# MCXN947_cm33_core0 register map
Vendor: nxp.com; File version: 1.0
CPU: CM33 r2p0, little endian, MPU, FPU, VTOR, 3 interrupt priority bits
Registers are 32-bit, read-write, reset 0x0 unless marked. A register's access mark holds for its fields unless they carry their own. Offsets are from the block's base; [hi:lo] are bit positions; {n}, {i} and the like mark numbered series; 'fields as' and 'values as' point back to an identical list.

## SYSCON0 (part 2 of 2) — SYSCON
Base 0x40000000
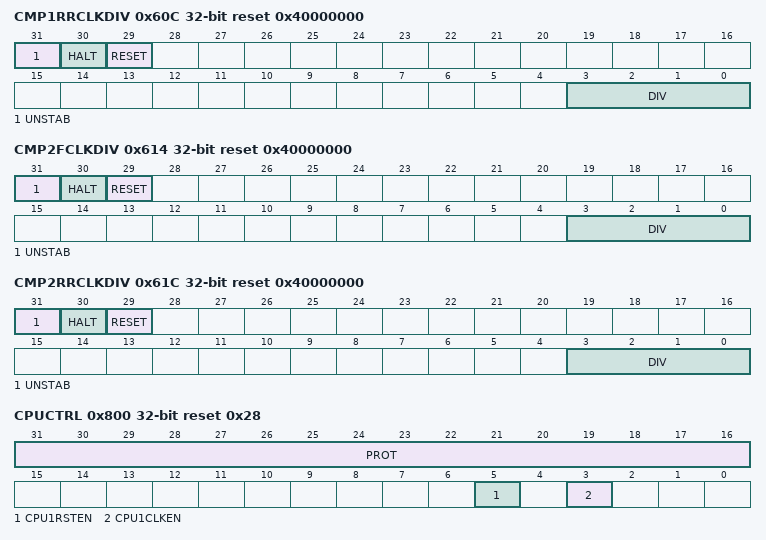
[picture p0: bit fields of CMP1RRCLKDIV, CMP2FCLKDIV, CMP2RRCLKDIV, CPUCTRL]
0x60C CMP1RRCLKDIV reset 0x40000000 — CMP1 Round Robin Clock Division
  [31] UNSTAB ro — Divider status flag
    0=STABLE (Divider clock is stable); 1=ONGOING (Clock frequency is not stable)
  [30] HALT — Halts the divider counter
    0=RUN (Divider clock is running); 1=HALT (Divider clock is stopped)
  [29] RESET — Resets the divider counter
    0=RELEASED (Divider is not reset); 1=ASSERTED (Divider is reset)
  [3:0] DIV — Clock divider value
0x610 CMP2FCLKSEL reset 0x7 — CMP2 Function Clock Source Select
  [2:0] SEL — Selects the CMP2 function clock
    0=No clock; 1=PLL0 clock; 2=FRO_HF clock; 3=FRO_12M clock; 4=CLKIN clock; 5=PLL1_clk0 clock; 6=USB PLL clock; 7=No clock
0x614 CMP2FCLKDIV reset 0x40000000 — CMP2 Function Clock Division
  fields as CMP1RRCLKDIV
0x618 CMP2RRCLKSEL reset 0x7 — CMP2 Round Robin Clock Source Select
  [2:0] SEL — Selects the CMP2 round robin clock
    0=No clock; 1=PLL0 clock; 2=FRO_HF clock; 3=FRO_12M clock; 4=CLKIN clock; 5=PLL1_clk0 clock0; 6=USB PLL clock; 7=No clock
0x61C CMP2RRCLKDIV reset 0x40000000 — CMP2 Round Robin Clock Division
  fields as CMP1RRCLKDIV
0x800 CPUCTRL reset 0x28 — CPU Control for Multiple Processors
  [31:16] PROT wo — Write Protect
    0xC0C4=PROT (For write operation to have an effect.)
  [5] CPU1RSTEN — CPU1 reset
    0=RELEASED (The CPU1 is not reset.); 1=ASSERTED (The CPU1 is reset.)
  [3] CPU1CLKEN — Enables the CPU1 clock
    0=DISABLE (The CPU1 clock is not enabled); 1=ENABLE (The CPU1 clock is enabled)
0x804 CPBOOT — Coprocessor Boot Address
  [31:7] CPBOOT — Coprocessor Boot VTOR Address [31:7] for CPU1
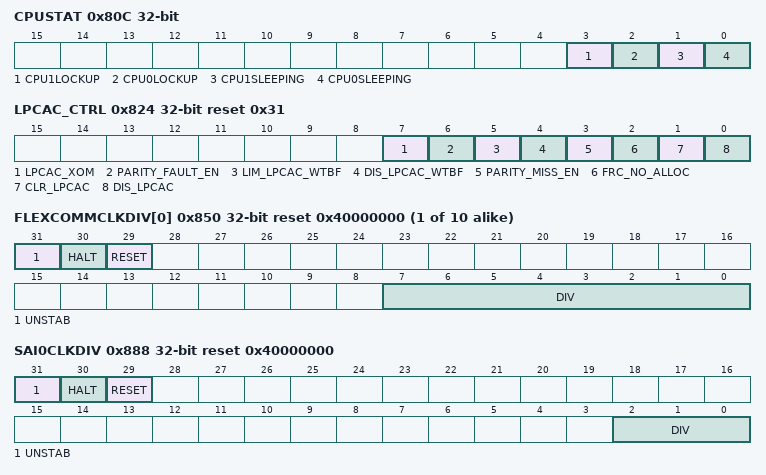
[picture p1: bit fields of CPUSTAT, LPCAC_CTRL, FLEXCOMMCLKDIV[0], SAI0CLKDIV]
0x80C CPUSTAT ro — CPU Status
  [3] CPU1LOCKUP — CPU1 lockup state
    0=AWAKE (CPU is not in lockup); 1=SLEEPING (CPU is in lockup)
  [2] CPU0LOCKUP — CPU0 lockup state
    values as CPU1LOCKUP
  [1] CPU1SLEEPING — CPU1 sleeping state
    0=AWAKE (CPU is not sleeping); 1=SLEEPING (CPU is sleeping)
  [0] CPU0SLEEPING — CPU0 sleeping state
    0=AWAKE (CPU is not sleeping); 1=SLEEPING (CPU is sleeping)
0x824 LPCAC_CTRL reset 0x31 — LPCAC Control
  [7] LPCAC_XOM — LPCAC XOM(eXecute-Only-Memory) attribute control
    0=DISABLE (Disabled.); 1=ENABLE (Enabled.)
  [6] PARITY_FAULT_EN — Enable parity error report.
    0=DISABLE (Disables parity error report); 1=ENABLE (Enables parity error report)
  [5] LIM_LPCAC_WTBF — Limit LPCAC Write Through Buffer.
    0=DISABLE (Write buffer enabled when transaction is bufferable.); 1=ENABLE (Write buffer enabled when transaction is cacheable and bufferable)
  [4] DIS_LPCAC_WTBF — Disable LPCAC Write Through Buffer.
    0=DISABLE (Enables write through buffer); 1=ENABLE (Disables write through buffer)
  [3] PARITY_MISS_EN — Enables parity miss.
    0=DISABLE (Disabled); 1=ENABLE (Enables parity, miss on parity error)
  [2] FRC_NO_ALLOC — Forces no allocation.
    0=ENABLE (Forces allocation); 1=DISABLE (Forces no allocation)
  [1] CLR_LPCAC — Clears the cache function.
    0=ENABLE (Unclears the cache); 1=DISABLE (Clears the cache)
  [0] DIS_LPCAC — Disables/enables the cache function.
    0=ENABLE (Enabled); 1=DISABLE (Disabled)
{0x850+4i} FLEXCOMMCLKDIV[{i}] (i=0..9) reset 0x40000000 — LP_FLEXCOMM Clock Divider
  [31] UNSTAB ro — Divider status flag
    values as CMP1RRCLKDIV.UNSTAB
  [30] HALT — Halts the divider counter
    values as CMP1RRCLKDIV.HALT
  [29] RESET — Resets the divider counter
    values as CMP1RRCLKDIV.RESET
  [7:0] DIV — Clock divider value
0x878 UTICKCLKSEL reset 0x2 — UTICK Function Clock Source Select
  [1:0] SEL — Selects the clock source
    0=clk_in; 1=xtal32k[2]; 2=clk_1m clock; 3=No clock
0x880 SAI0CLKSEL reset 0x7 — SAI0 Function Clock Source Select
  [2:0] SEL — Selects the clock source
    0=No clock; 1=PLL0 clock; 2=CLKIN clock; 3=FRO_HF clock; 4=PLL1_CLK0 clock; 5=No clock; 6=USB PLL clock; 7=No clock
0x884 SAI1CLKSEL reset 0x7 — SAI1 Function Clock Source Select
  fields as SAI0CLKSEL
0x888 SAI0CLKDIV reset 0x40000000 — SAI0 Function Clock Division
  [31] UNSTAB ro — Divider status flag
    values as CMP1RRCLKDIV.UNSTAB
  [30] HALT — Halts the divider counter
    values as CMP1RRCLKDIV.HALT
  [29] RESET — Resets the divider counter
    values as CMP1RRCLKDIV.RESET
  [2:0] DIV — Clock divider value
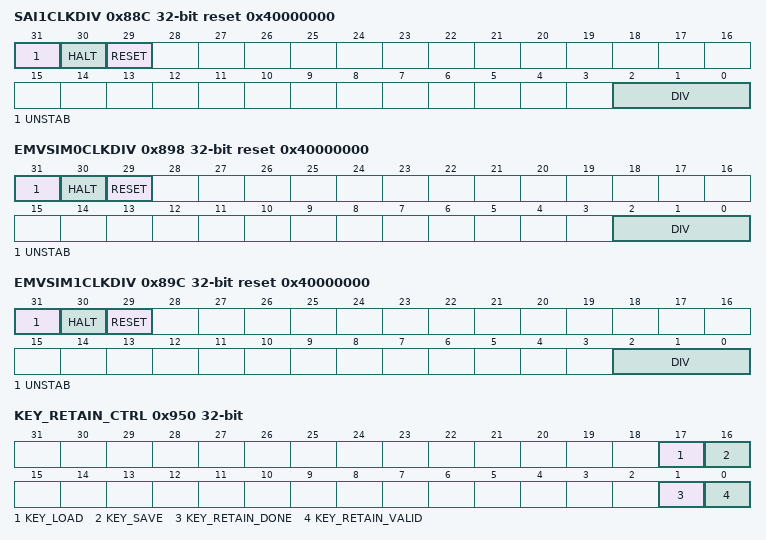
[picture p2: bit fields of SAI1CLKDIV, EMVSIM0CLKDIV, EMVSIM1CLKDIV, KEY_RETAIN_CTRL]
0x88C SAI1CLKDIV reset 0x40000000 — SAI1 Function Clock Division
  fields as SAI0CLKDIV
0x890 EMVSIM0CLKSEL reset 0x7 — EMVSIM0 Clock Source Select
  [2:0] SEL — Selects the EMVSIM0 function clock source
    0=No clock; 1=PLL0 clock; 2=CLKIN clock; 3=FRO_HF clock; 4=FRO_12M clock; 5=PLL1_clk0 clock0; 6=No clock; 7=No clock
0x894 EMVSIM1CLKSEL reset 0x7 — EMVSIM1 Clock Source Select
  [2:0] SEL — Selects the EMVSIM1 function clock source
    values as EMVSIM0CLKSEL.SEL
0x898 EMVSIM0CLKDIV reset 0x40000000 — EMVSIM0 Function Clock Division
  fields as SAI0CLKDIV
0x89C EMVSIM1CLKDIV reset 0x40000000 — EMVSIM1 Function Clock Division
  fields as SAI0CLKDIV
0x950 KEY_RETAIN_CTRL — Key Retain Control
  [17] KEY_LOAD — Do not set both KEY_SAVE and KEY_LOAD at the same time
    0=DISABLE (Key load sequence is disabled.); 1=ENABLE (Key load sequence is enabled.)
  [16] KEY_SAVE — Do not set both KEY_SAVE and KEY_LOAD at the same time
    0=DISABLE (Key save sequence is disabled.); 1=ENABLE (Key save sequence is enabled.)
  [1] KEY_RETAIN_DONE ro — Indicates the successful completion of the key_save or key_load routine. Once set, to clear the key_retain_done flag, both key_save and key_load should be cleared by software.
    0=NOT_DONE (Key save / load sequence has not completed.); 1=DONE (Key save / load sequence has completed.)
  [0] KEY_RETAIN_VALID ro — Indicates if the PUF key has been retained in the VBAT domain and has not been reset or otherwise invalidated by software.
    0=NOT_VALID (PUF key is not retained in VBAT domain.); 1=VALID (PUF key is retained in VBAT domain.)
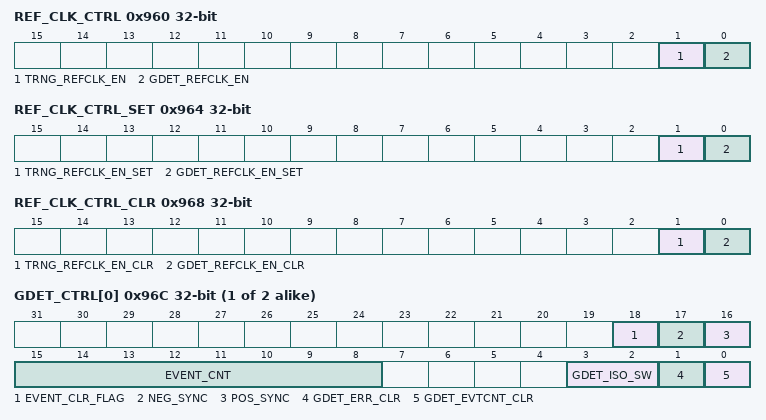
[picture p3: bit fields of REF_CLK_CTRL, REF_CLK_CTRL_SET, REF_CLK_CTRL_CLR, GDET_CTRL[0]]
0x960 REF_CLK_CTRL — FRO 48MHz Reference Clock Control
  [1] TRNG_REFCLK_EN — ELS TRNG reference clock enable bit
    0=DISABLE (Disabled.); 1=ENABLE (Enabled)
  [0] GDET_REFCLK_EN — GDET reference clock enable bit
    0=DISABLE (Disabled.); 1=ENABLE (Enabled)
0x964 REF_CLK_CTRL_SET wo — FRO 48MHz Reference Clock Control Set
  [1] TRNG_REFCLK_EN_SET — ELS TRNG reference clock enable set bit
    0=DISABLE (No effect.); 1=ENABLE (Set to 1)
  [0] GDET_REFCLK_EN_SET — GDET reference clock enable set bit
    0=DISABLE (No effect.); 1=ENABLE (Set to 1)
0x968 REF_CLK_CTRL_CLR wo — FRO 48MHz Reference Clock Control Clear
  [1] TRNG_REFCLK_EN_CLR — ELS TRNG reference clock enable clear bit
    0=DISABLE (No effect.); 1=ENABLE (Set to 0)
  [0] GDET_REFCLK_EN_CLR — GDET reference clock enable clear bit
    0=DISABLE (No effect.); 1=ENABLE (Set to 0)
{0x96C+4i} GDET_CTRL[{i}] (i=0..1) — GDET Control Register
  [18] EVENT_CLR_FLAG ro — Event counter cleared
    0=DISABLE (Event counter not cleared); 1=ENABLE (Event counter cleared)
  [17] NEG_SYNC ro — Negative glitch detected
    0=DISABLE (Negative glitch not detected); 1=ENABLE (Negative glitch detected)
  [16] POS_SYNC ro — Positive glitch detected
    0=DISABLE (Positive glitch not detected); 1=ENABLE (Positive glitch detected)
  [15:8] EVENT_CNT ro — Event count value
  [3:2] GDET_ISO_SW — GDET isolation control
    0=DISABLE0 (Isolation is disabled); 1=DISABLE1 (Isolation is disabled); 2=ENABLE (Isolation is enabled. When both GDET0_CTRL/GDET1_CTRL GDET_ISO_SW are "10", isolation_on is asserted.); 3=DISABLE3 (Isolation is disabled)
  [1] GDET_ERR_CLR — Clears GDET error status
    0=DISABLE (Error status not cleared); 1=ENABLE (Clears error status)
  [0] GDET_EVTCNT_CLR — Controls the GDET clean event counter
    0=DISABLE (Event counter not cleared); 1=ENABLE (Clears event counter)
0x980 ELS_OTP_LC_STATE ro reset 0x55 — Life Cycle State Register
  [7:0] OTP_LC_STATE — OTP life cycle state
0x984 ELS_OTP_LC_STATE_DP ro reset 0x55 — Life Cycle State Register (Duplicate)
  [7:0] OTP_LC_STATE_DP — OTP life cycle state
0x988 ELS_TEMPORAL_STATE
  [3:0] TEMPORAL_STATE
0x98C ELS_KDF_MASK — Key Derivation Function Mask
  [31:0] KDF_MASK — Key derivation function mask
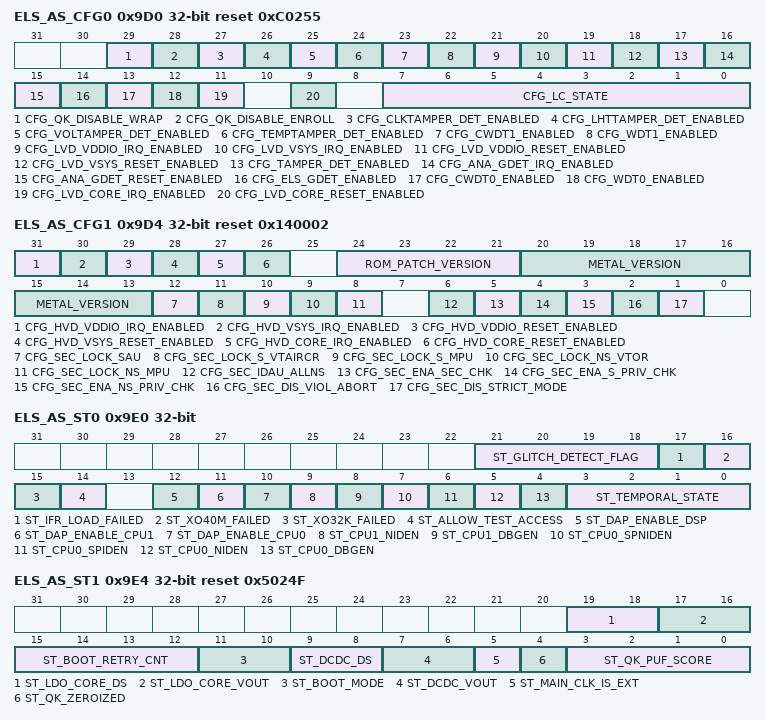
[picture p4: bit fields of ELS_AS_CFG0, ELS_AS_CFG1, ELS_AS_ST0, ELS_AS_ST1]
0x9D0 ELS_AS_CFG0 ro reset 0xC0255 — ELS AS Configuration
  [29] CFG_QK_DISABLE_WRAP — When QK PUF "qk_disable_wrap" input is driven 1, this bit indicates state 1
  [28] CFG_QK_DISABLE_ENROLL — When QK PUF "qk_disable_enroll" input is driven 1, this bit indicates state 1
  [27] CFG_CLKTAMPER_DET_ENABLED — When clk tamper detector is enabled in VBAT, this bit indicates state 1.
  [26] CFG_LHTTAMPER_DET_ENABLED — When light tamper detector is enabled in VBAT, this bit indicates state 1.
  [25] CFG_VOLTAMPER_DET_ENABLED — When voltage tamper detector is enabled in VBAT, this bit indicates state 1.
  [24] CFG_TEMPTAMPER_DET_ENABLED — When temperature tamper detector is enabled in VBAT, this bit indicates state 1.
  [23] CFG_CWDT1_ENABLED — When Code WatchDog Timer 1 is activated, this bit indicates state 1.
  [22] CFG_WDT1_ENABLED — When WatchDog Timer 1 is activated, this bit indicates state 1.
  [21] CFG_LVD_VDDIO_IRQ_ENABLED — When SPC VDDIO LVD analog detector are turned on and VDDIO LVD irq are enabled, this bit indicates state 1.
  [20] CFG_LVD_VSYS_IRQ_ENABLED — When SPC VSYS LVD analog detector are turned on and VSYS LVD irq are enabled, this bit indicates state 1.
  [19] CFG_LVD_VDDIO_RESET_ENABLED — When SPC VDDIO LVD analog detector are turned on and VDDIO LVD reset are enabled, this bit indicates state 1.
  [18] CFG_LVD_VSYS_RESET_ENABLED — When SPC VSYS LVD analog detector are turned on and VSYS LVD reset are enabled, this bit indicates state 1.
  [17] CFG_TAMPER_DET_ENABLED — When tamper detector is enabled in TDET, this bit indicates state 1.
  [16] CFG_ANA_GDET_IRQ_ENABLED — When SPC analog glitch detect IRQ is enabled, this bit indicates state 1
  [15] CFG_ANA_GDET_RESET_ENABLED — When SPC analog glitch detect reset is enabled, this bit indicates state 1
  [14] CFG_ELS_GDET_ENABLED — When either GDET is enabled, this bit indicates state 1.
  [13] CFG_CWDT0_ENABLED — When Code WatchDog Timer 0 is activated, this bit indicates state 1
  [12] CFG_WDT0_ENABLED — When WatchDog Timer 0 is activated, this bit indicates state 1
  [11] CFG_LVD_CORE_IRQ_ENABLED — When SPC CORE LVD analog detector are turned on, and CORE LVD IRQ are enabled, this bit indicates state 1.
  [9] CFG_LVD_CORE_RESET_ENABLED — When SPC CORE LVD analog detector are turned on, and CORE LVD reset are enabled, this bit indicates state 1.
  [7:0] CFG_LC_STATE — LC state configuration bit
0x9D4 ELS_AS_CFG1 ro reset 0x140002 — ELS AS Configuration1
  [31] CFG_HVD_VDDIO_IRQ_ENABLED — When SPC VDDIO HVD analog detector are turned on and VDDIO HVD irq are enabled, this bit indicates state 1.
  [30] CFG_HVD_VSYS_IRQ_ENABLED — When SPC VSYS HVD analog detector are turned on and VSYS HVD irq are enabled, this bit indicates state 1.
  [29] CFG_HVD_VDDIO_RESET_ENABLED — When SPC VDDIO HVD analog detector are turned on and VDDIO HVD reset are enabled, this bit indicates state 1.
  [28] CFG_HVD_VSYS_RESET_ENABLED — When SPC VSYS HVD analog detector are turned on and VSYS HVD reset are enabled, this bit indicates state 1.
  [27] CFG_HVD_CORE_IRQ_ENABLED — When SPC CORE HVD analog detector are turned on, and CORE HVD IRQ are enabled, this bit indicates state 1.
  [26] CFG_HVD_CORE_RESET_ENABLED — When SPC CORE HVD analog detector are turned on, and CORE HVD reset are enabled, this bit indicates state 1.
  [24:21] ROM_PATCH_VERSION
  [20:13] METAL_VERSION
  [12] CFG_SEC_LOCK_SAU — When the LOCK_SAU bits in CPU0_LOCK_REG on the AHB secure controller are not equal to 10, this bit indicates state 1
  [11] CFG_SEC_LOCK_S_VTAIRCR — When the LOCK_S_VTAIRCR bits in CPU0_LOCK_REG on the AHB secure controller are not equal to 10, this bit indicates state 1
  [10] CFG_SEC_LOCK_S_MPU — When the LOCK_S_MPU bits in CPU0_LOCK_REG on the AHB secure controller are not equal to 10, this bit indicates state 1
  [9] CFG_SEC_LOCK_NS_VTOR — When the LOCK_NS_VTOR bits in CPU0_LOCK_REG on the AHB secure controller are not equal to 10, this bit indicates state 1
  [8] CFG_SEC_LOCK_NS_MPU — When the LOCK_NS_MPU bits in CPU0_LOCK_REG on the AHB secure controller are not equal to 10, this bit indicates state 1
  [6] CFG_SEC_IDAU_ALLNS — When the IDAU_ALL_NS bits in MISC_CTRL_REG and MISC_CTRL_DP_REG on the AHB secure controller are equal to 01, this bit indicates state 1
  [5] CFG_SEC_ENA_SEC_CHK — When the ENABLE_SECURE_CHECKING bits in MISC_CTRL_REG and MISC_CTRL_DP_REG on the AHB secure controller are not equal to 10, this bit indicates state 1
  [4] CFG_SEC_ENA_S_PRIV_CHK — When the ENABLE_S_PRIV_CHECK bits in MISC_CTRL_REG and MISC_CTRL_DP_REG on the AHB secure controller are not equal to 10, this bit indicates state 1
  [3] CFG_SEC_ENA_NS_PRIV_CHK — When the ENABLE_NS_PRIV_CHECK bits in MISC_CTRL_REG and MISC_CTRL_DP_REG on the AHB secure controller are not equal to 10, this bit indicates state 1
  [2] CFG_SEC_DIS_VIOL_ABORT — When the DISABLE_VIOLATION_ABORT bits in MISC_CTRL_REG and MISC_CTRL_DP_REG on the AHB secure controller are not equal to 10, this bit indicates state 1
  [1] CFG_SEC_DIS_STRICT_MODE — When CFG_SEC_ENA_SEC_CHK indicates state 0 or when DISABLE_STRICT_MODE bits in MISC_CTRL_REG and MISC_CTRL_DP_REG on the AHB secure controller are equal to 01, this bit indicates state 1
0x9D8 ELS_AS_CFG2 ro reset 0xFFFFFFFF — ELS AS Configuration2
  [31:0] CFG_ELS_CMD_EN — ELS configuration command enable bit
0x9DC ELS_AS_CFG3 ro reset not defined — ELS AS Configuration3
  [31:0] DEVICE_TYPE — Device type identification data
0x9E0 ELS_AS_ST0 ro — ELS AS State Register
  [21:18] ST_GLITCH_DETECT_FLAG — GLITCH_DETECT_FLAG is state of 4-bit Glitch Ripple Counter output.
  [17] ST_IFR_LOAD_FAILED — When IFR load fail flag is state 1, this bit indicates state 1
  [16] ST_XO40M_FAILED — When XO40M oscillation fail flag is state 1, this bit indicates state 1
  [15] ST_XO32K_FAILED — When XO32K oscillation fail flag is state 1, this bit indicates state 1
  [14] ST_ALLOW_TEST_ACCESS — When JTAG TAP access is allowed, this bit indicates state 1.
  [12] ST_DAP_ENABLE_DSP — When DAP to AP3 for DSP (CoolFlux) debug access is allowed, this bit indicates state 1
  [11] ST_DAP_ENABLE_CPU1 — When DAP to AP1 for CPU1 (CM33) debug access is allowed, this bit indicates state 1.
  [10] ST_DAP_ENABLE_CPU0 — When DAP to AP0 for CPU0 (CM33) debug access is allowed, this bit indicates state 1
  [9] ST_CPU1_NIDEN — When CPU1 (CM33) "niden" input is state 1, this bit indicates state 1.
  [8] ST_CPU1_DBGEN — When CPU1 (CM33) "deben" input is state 1, this bit indicates state 1.
  [7] ST_CPU0_SPNIDEN — When CPU0 (CM33) "spniden" input is state 1, this bit indicates state 1
  [6] ST_CPU0_SPIDEN — When CPU0 (CM33) "spiden" input is state 1, this bit indicates state 1
  [5] ST_CPU0_NIDEN — When CPU0 (CM33) "niden" input is state 1, this bit indicates state 1
  [4] ST_CPU0_DBGEN — When CPU0 (CM33) "deben" input is state 1, this bit indicates state 1
  [3:0] ST_TEMPORAL_STATE — TEMPORAL_STATE[3:0] in the ELS_TEMPORAL_STATE register reflects this register
0x9E4 ELS_AS_ST1 ro reset 0x5024F — ELS AS State1
  [19:18] ST_LDO_CORE_DS — LDO_CORE drive strength setting. Default is normal drive.
  [17:16] ST_LDO_CORE_VOUT — VOUT[1:0] setting on LDO Core register in SPC block will reflect to this register. Default is 1.0V
  [15:12] ST_BOOT_RETRY_CNT — BOOT_RETRY_CNT[3:0] in the ELS_BOOT_RETRY_CNT register reflects this register
  [11:10] ST_BOOT_MODE — ISP pin status during boot. By default ISP pin is pulled up. If want to enter ISP mode during boot, ISP pin should be pull down when out of reset.
  [9:8] ST_DCDC_DS — DCDC drive strength setting. Default is normal drive.
  [7:6] ST_DCDC_VOUT — VOUT[1:0] setting on DCDC0 register in SPC block will reflect to this register. Default is 1.0V
  [5] ST_MAIN_CLK_IS_EXT — When MAIN_CLK is running from external clock source either XO32M, XO32K or GPIO CLKIN, this bit indicates state 1
  [4] ST_QK_ZEROIZED — This register bit indicates the state of "qk_zeroized" output from QK PUF block
  [3:0] ST_QK_PUF_SCORE — These register bits indicate the state of "qk_puf_score[3:0]" outputs from QK PUF block
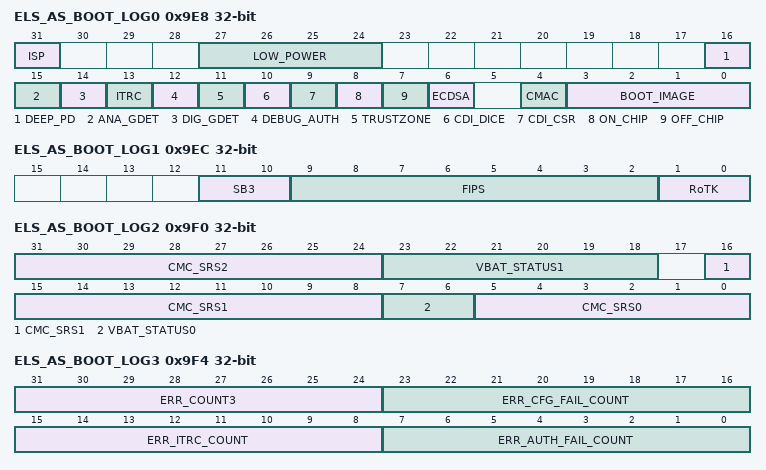
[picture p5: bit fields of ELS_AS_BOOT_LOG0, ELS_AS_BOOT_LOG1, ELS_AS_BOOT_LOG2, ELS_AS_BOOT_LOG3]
0x9E8 ELS_AS_BOOT_LOG0 ro — Boot state captured during boot: Main ROM log
  [31] ISP — ISP pin state at boot time. ROM copies CMC->MR0[0].
  [27:24] LOW_POWER — Last low-power mode value. ROM copies SPC_LP_MODE field from SPC->SC[7:4].
  [16] DEEP_PD — Boot from deep-power down state.
  [15] ANA_GDET — Analog glitch detector is enabled during boot.
  [14] DIG_GDET — Digital glitch detector is enabled during boot.
  [13] ITRC — ITRC zeroize event is handled in this session of boot.
  [12] DEBUG_AUTH — Debug authentication done in this session prior to boot.
  [11] TRUSTZONE — TrustZone preset data is loaded during this boot.
  [10] CDI_DICE — CDI per DICE specification is computed on this boot.
  [9] CDI_CSR — CDI based device keys are derived for CSR harvesting on this boot.
  [8] ON_CHIP — On-chip Prince is enabled during boot.
  [7] OFF_CHIP — Off-chip Prince is enabled during boot.
  [6] ECDSA — ECDSA P-384 verification is done on this boot.
  [4] CMAC — CMAC verify is used instead of ECDSA verify on this boot.
  [3:0] BOOT_IMAGE — Boot image source used during this boot.
    0=Internal flash image 0; 1=Internal flash image 1; 2=FlexSPI flash image 0; 3=FlexSPI flash image 1; 4=Recovery SPI flash image; 5=Serial boot image (write-memory and execute ISP command used); 6=Receive SB3 containing SB_JUMP command is used; 7=Customer SBL/recovery image (Bank1 IFR0); 8=NXP MAD recovery image (Bank1 IFR0); 9=NXP ROM extension (NMPA - Bank0 IFR0)
0x9EC ELS_AS_BOOT_LOG1 ro — Boot state captured during boot: N-boot library log
  [11:10] SB3 — SB3 type (valid after nboot_sb3_load_manifest()).
    0=CUSTOMER (customer fw load/update file.); 1=NXP (NXP Provisioning FW.); 2=OEM (ELS signed OEM Provisioning FW.)
  [9:2] FIPS — FIPS self-test is executed and PASS during this boot. When a bit is set, means self-test is executed and it FAILS. When a bit is clear, means corresponding self-test is executed and PASS or it is not executed.
  [1:0] RoTK — RoTK index used for this boot.
0x9F0 ELS_AS_BOOT_LOG2 ro — Boot state captured during boot: Hardware status signals log
  [31:24] CMC_SRS2 — CMC->SRS[31:24]
  [23:18] VBAT_STATUS1 — VBAT->STATUSA[11:6] | ~VBAT->STATUSB[11:6]
  [16:8] CMC_SRS1 — CMC->SRS[16:8]
  [7:6] VBAT_STATUS0 — VBAT->STATUSA[1:0] | ~VBAT->STATUSB[1:0]
  [5:0] CMC_SRS0 — CMC->SRS[5:0]
0x9F4 ELS_AS_BOOT_LOG3 ro — Boot state captured during boot: Security log
  [31:24] ERR_COUNT3 — CFPA->ERR_COUNT3[7:0]
  [23:16] ERR_CFG_FAIL_COUNT — CFPA->ERR_CFG_FAIL_COUNT[7:0]
  [15:8] ERR_ITRC_COUNT — CFPA->ERR_ITRC_COUNT[7:0]
  [7:0] ERR_AUTH_FAIL_COUNT — CFPA->ERR_AUTH_FAIL_COUNT[7:0]
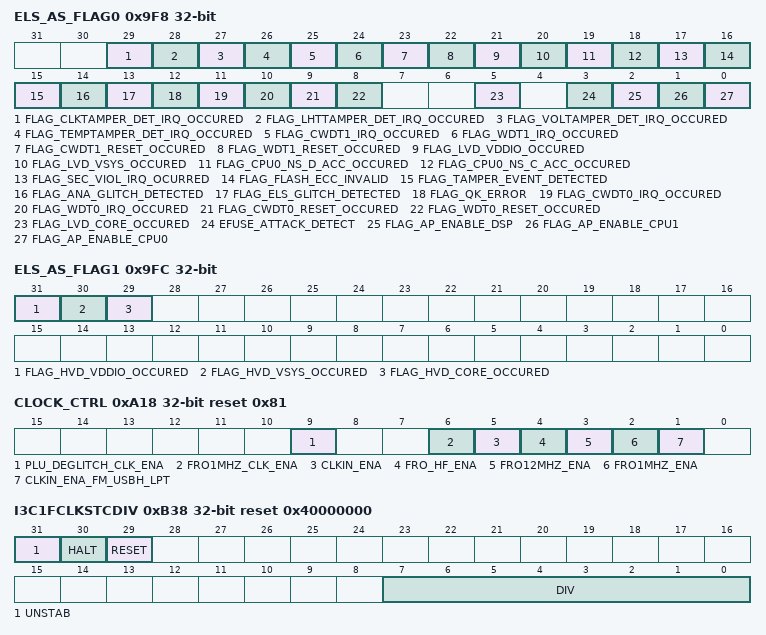
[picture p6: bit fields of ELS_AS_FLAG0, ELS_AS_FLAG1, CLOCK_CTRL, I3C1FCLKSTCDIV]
0x9F8 ELS_AS_FLAG0 ro
  [all] fields
    0=DISABLE (Not Triggered); 1=ENABLE (Triggered)
  [29] FLAG_CLKTAMPER_DET_IRQ_OCCURED — This flag bit is set as 1 when clock temper IRQ is enabled and IRQ event is triggered. This register is cleared 0 by PMC reset event.
  [28] FLAG_LHTTAMPER_DET_IRQ_OCCURED — This flag bit is set as 1 when light temper IRQ is enabled and IRQ event is triggered. This register is cleared 0 by PMC reset event.
  [27] FLAG_VOLTAMPER_DET_IRQ_OCCURED — This flag bit is set as 1 when voltage temper IRQ is enabled and IRQ event is triggered. This register is cleared 0 by PMC reset event.
  [26] FLAG_TEMPTAMPER_DET_IRQ_OCCURED — This flag bit is set as 1 when temperature temper IRQ is enabled and IRQ event is triggered. This register is cleared 0 by PMC reset event.
  [25] FLAG_CWDT1_IRQ_OCCURED — This flag bit is set as 1 when Code WatchDog Timer 1 IRQ is enabled and IRQ event is triggered. This register is cleared 0 by PMC reset event.
  [24] FLAG_WDT1_IRQ_OCCURED — This flag bit is set as 1 when WatchDog Timer 1 IRQ is enabled and IRQ event is triggered. This register is cleared 0 by PMC reset event.
  [23] FLAG_CWDT1_RESET_OCCURED — This flag bit is set as 1 when Code WatchDog Timer 1 reset is enabled and reset event is triggered. This register is cleared 0 by AO domain POR.
  [22] FLAG_WDT1_RESET_OCCURED — This flag bit is set as 1 when WatchDog Timer 1 reset is enabled and reset event is triggered. This register is cleared 0 by AO domain POR.
  [21] FLAG_LVD_VDDIO_OCCURED — This flag register is set 1 when VDD LVD event is triggered. This register is cleared 0 by PMC reset event.
  [20] FLAG_LVD_VSYS_OCCURED — This flag register is set 1 when VDD_SYS LVD event is triggered. This register is cleared 0 by PMC reset event.
  [19] FLAG_CPU0_NS_D_ACC_OCCURED — This flag bit is set as 1 when CPU0 (CM33) makes non-secure data transactions. This register is cleared 0 by PMC reset event.
  [18] FLAG_CPU0_NS_C_ACC_OCCURED — This flag bit is set as 1 when CPU0 (CM33) makes non-secure code transactions. This register is cleared 0 by PMC reset event.
  [17] FLAG_SEC_VIOL_IRQ_OCURRED — This flag bit is set as 1 when security violation is indicated from FLASH sub-system or AHB bus matrix.
  [16] FLAG_FLASH_ECC_INVALID — This flag bit is set as 1 when FLASH controller indicates ECC error. This register is cleared 0 by PMC reset event.
  [15] FLAG_TAMPER_EVENT_DETECTED — This flag bit is set as 1 when tamper event is flagged from TDET. This register is cleared 0 by AO domain POR or by PMC reset event, if tamper detection event is cleared by software.
  [14] FLAG_ANA_GLITCH_DETECTED — This flag bit is set as 1 when ANALOG GDET error is flagged in SYSCON block. This register is cleared 0 by PMC reset event.
  [13] FLAG_ELS_GLITCH_DETECTED — This flag bit is set as 1 when GDET error is flagged. This register is cleared 0 by PMC reset event.
  [12] FLAG_QK_ERROR — This flag bit is set as 1 when QK_ERROR is flagged from QK PUF block. This register is cleared 0 by PMC reset event.
  [11] FLAG_CWDT0_IRQ_OCCURED — This flag bit is set as 1 when Code WatchDog Timer 0 IRQ is enabled and IRQ event is triggered. This register is cleared 0 by PMC reset event.
  [10] FLAG_WDT0_IRQ_OCCURED — This flag bit is set as 1 when WatchDog Timer 0 IRQ is enabled and IRQ event is triggered. This register is cleared 0 by PMC reset event.
  [9] FLAG_CWDT0_RESET_OCCURED — This flag bit is set as 1 when Code WatchDog Timer 0 reset is enabled and reset event is triggered. This register is cleared 0 by AO domain POR.
  [8] FLAG_WDT0_RESET_OCCURED — This flag bit is set as 1 when WatchDog Timer 0 reset is enabled and reset event is triggered. This register is cleared 0 by AO domain POR.
  [5] FLAG_LVD_CORE_OCCURED — This flag register is set 1 when VDD_CORE LVD event is triggered. This register is cleared 0 by PMC reset event.
  [3] EFUSE_ATTACK_DETECT — OTPC can output attack_detect signal when it detects attack when load shadow registers. The output will be cleared by reset. ELS_AS_FLAG is reset by PoR, so the status can be recorded.
  [2] FLAG_AP_ENABLE_DSP — This flag bit is set as 1 when DAP enables AP3 for DSP (CoolFlux) debug access. The register is cleared 0 by PMC reset event.
  [1] FLAG_AP_ENABLE_CPU1 — This flag bit is set as 1 when DAP enables AP1 for CPU1 (CM33) debug access. The register is cleared 0 by PMC reset event.
  [0] FLAG_AP_ENABLE_CPU0 — This flag bit is set as 1 when DAP enables AP0 for CPU0 (CM33) debug access. The register is cleared 0 by PMC reset event.
0x9FC ELS_AS_FLAG1 ro
  [all] fields
    0=DISABLE (Not Triggered); 1=ENABLE (Triggered)
  [31] FLAG_HVD_VDDIO_OCCURED — This flag bit is set as 1 when HVD from VDD power domain is triggered
  [30] FLAG_HVD_VSYS_OCCURED — This flag bit is set as 1 when HVD from VDD_SYS power domain is triggered
  [29] FLAG_HVD_CORE_OCCURED — This flag bit is set as 1 when HVD from VDD_CORE power domain is triggered.
0xA18 CLOCK_CTRL reset 0x81 — Clock Control
  [all] fields
    0=DISABLE (Clock is not enabled); 1=ENABLE (Clock is enabled)
  [9] PLU_DEGLITCH_CLK_ENA — Enables clocks FRO_1MHz and FRO_12MHz for PLU deglitching.
  [6] FRO1MHZ_CLK_ENA — Enables FRO_1MHz clock for clock muxing in clock gen
  [5] CLKIN_ENA — Enables clk_in clock for MICFIL, EMVSIM0/1, CAN0/1, I3C0/1, SAI0/1, SINC Filter (SINC), TSI, USBFS, SCT, uSDHC, clkout.
  [4] FRO_HF_ENA — Enables FRO HF clock for the Frequency Measure module
  [3] FRO12MHZ_ENA — Enables the FRO_12MHz clock for the Flash, LPTIMER0/1, and Frequency Measurement modules
  [2] FRO1MHZ_ENA — Enables the FRO_1MHz clock for RTC module and for UTICK
  [1] CLKIN_ENA_FM_USBH_LPT — Enables the clk_in clock for the Frequency Measurement, USB HS and LPTIMER0/1 modules.
0xB30 I3C1FCLKSEL reset 0x7 — I3C1 Functional Clock Selection
  [2:0] SEL — I3C1 clock select
    0=No clock; 1=PLL0 clock; 2=CLKIN clock; 3=FRO_HF clock; 4=No clock; 5=PLL1_clk0 clock; 6=USB PLL clock; 7=No clock
0xB34 I3C1FCLKSTCSEL reset 0x7 — Selects the I3C1 Time Control clock
  [2:0] SEL — I3C1 FCLK_STC clock select
    0=I3C1 functional clock I3C1FCLK; 1=FRO_1M clock; {v}=No clock (v=2..7)
0xB38 I3C1FCLKSTCDIV reset 0x40000000 — I3C1 FCLK_STC Clock Divider
  fields as FLEXCOMMCLKDIV[0]
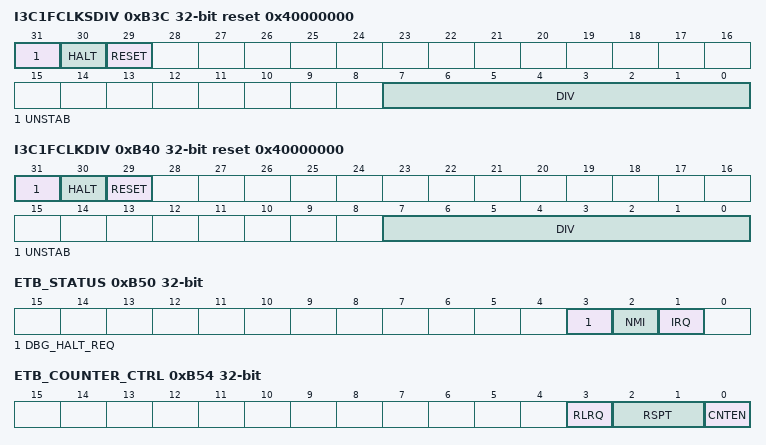
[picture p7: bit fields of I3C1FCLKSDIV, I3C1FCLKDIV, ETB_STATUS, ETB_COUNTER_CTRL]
0xB3C I3C1FCLKSDIV reset 0x40000000 — I3C1 FCLK Slow clock Divider
  fields as FLEXCOMMCLKDIV[0]
0xB40 I3C1FCLKDIV reset 0x40000000 — I3C1 Functional Clock FCLK Divider
  fields as FLEXCOMMCLKDIV[0]
0xB44 I3C1FCLKSSEL — I3C1 FCLK Slow Selection
  [2:0] SEL — I3C1 FCLK Slow Clock Select
    0=FRO_1M clock; {v}=No clock (v=1..7)
0xB50 ETB_STATUS — ETB Counter Status Register
  [3] DBG_HALT_REQ ro — Debug halt request
    0=DISABLE (The debug halt request signal is not asserted); 1=ENABLE (The debug halt request signal is asserted when the ETB count expires)
  [2] NMI — ETB NMI
    0=DISABLE (ETB NMI is not asserted); 1=ENABLE (ETB NMI is asserted. Write 1 to clear it.)
  [1] IRQ — ETB Interrupt
    0=DISABLE (ETB interrupt is not asserted); 1=ENABLE (ETB interrupt is asserted when ETB count expires. Write 1 to clear it.)
0xB54 ETB_COUNTER_CTRL — ETB Counter Control Register
  [3] RLRQ — Reload request
    0=DISABLE (No effect); 1=ENABLE (Clears pending debug halt, NMI, or IRQ interrupt requests)
  [2:1] RSPT — Response Type
    0=No response when the ETB count expires; 1=interrupt (Generates a normal interrupt when the ETB count expires); 2=NMI (Generates an NMI interrupt when the ETB count expires); 3=debug_halt (Generates a debug halt when the ETB count expires via CPU0 CTICHIN[2])
  [0] CNTEN — Enables the ETB counter
    0=DISABLE (ETB counter is disabled); 1=ENABLE (ETB counter is enabled)
0xB58 ETB_COUNTER_RELOAD
  [10:0] RELOAD — Byte count reload value
0xB5C ETB_COUNTER_VALUE ro
  [10:0] COUNTER_VALUE — Byte count counter value
0xB60 GRAY_CODE_LSB — Gray to Binary Converter Gray code_gray[31:0]
  [31:0] code_gray_31_0 — Gray code [31:0]
0xB64 GRAY_CODE_MSB — Gray to Binary Converter Gray code_gray[41:32]
  [9:0] code_gray_41_32 — Gray code [41:32]
0xB68 BINARY_CODE_LSB ro — Gray to Binary Converter Binary Code [31:0]
  [31:0] code_bin_31_0 — Binary code [31:0]
0xB6C BINARY_CODE_MSB ro — Gray to Binary Converter Binary Code [41:32]
  [9:0] code_bin_41_32 — Binary code [41:32]
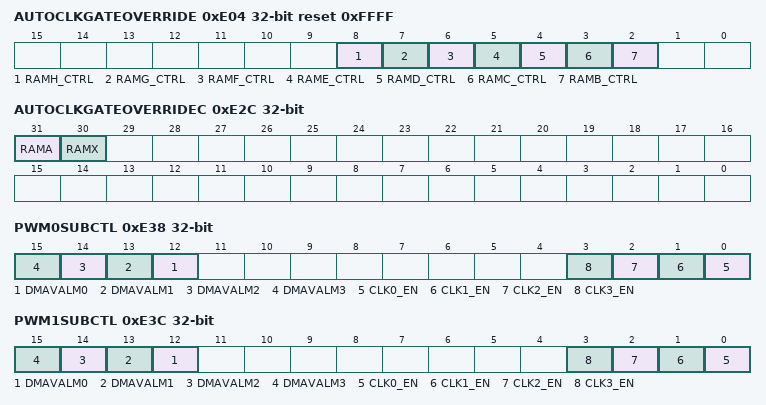
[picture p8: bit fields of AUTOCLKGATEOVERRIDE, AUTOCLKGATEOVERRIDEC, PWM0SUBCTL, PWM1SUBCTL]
0xE04 AUTOCLKGATEOVERRIDE reset 0xFFFF — Control Automatic Clock Gating
  [all] fields
    0=DISABLE (Automatic clock gating is not overridden); 1=ENABLE (Automatic clock gating is overridden (Automatic clock gating is disabled).)
  [8] RAMH_CTRL — Controls automatic clock gating for the RAMG Controller
  [7] RAMG_CTRL — Controls automatic clock gating for the RAMG Controller
  [6] RAMF_CTRL — Controls automatic clock gating for the RAMF Controller
  [5] RAME_CTRL — Controls automatic clock gating for the RAMD Controller.
  [4] RAMD_CTRL — Controls automatic clock gating for the RAMD Controller
  [3] RAMC_CTRL — Controls automatic clock gating for the RAMC Controller
  [2] RAMB_CTRL — Controls automatic clock gating for the RAMB Controller
0xE2C AUTOCLKGATEOVERRIDEC — Control Automatic Clock Gating C
  [31] RAMA — Controls automatic clock gating of the RAMA controller
    values as the fields of AUTOCLKGATEOVERRIDE
  [30] RAMX — Controls automatic clock gating of the RAMX controller
    values as the fields of AUTOCLKGATEOVERRIDE
0xE38 PWM0SUBCTL — PWM0 Submodule Control
  [n+12] DMAVALM{n} (n=0..3) — PWM0 submodule {n} DMA compare value done mask
  [n] CLK{n}_EN (n=0..3) — Enables PWM0 SUB Clock{n}
0xE3C PWM1SUBCTL — PWM1 Submodule Control
  [n+12] DMAVALM{n} (n=0..3) — PWM1 submodule {n} DMA compare value done mask
  [n] CLK{n}_EN (n=0..3) — Enables PWM1 SUB Clock{n}
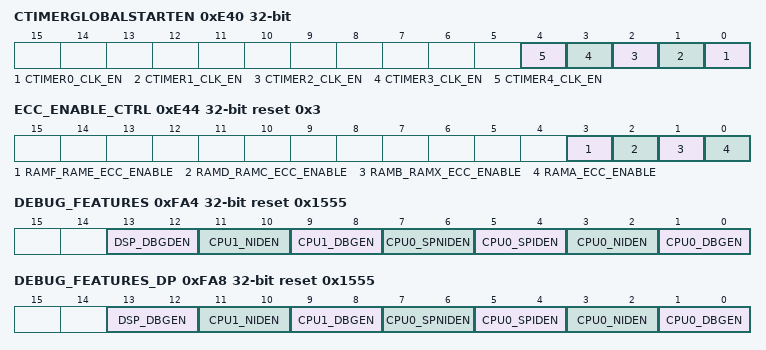
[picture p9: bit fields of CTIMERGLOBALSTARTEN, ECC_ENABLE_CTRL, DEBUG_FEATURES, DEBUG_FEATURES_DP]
0xE40 CTIMERGLOBALSTARTEN — CTIMER Global Start Enable
  [all] fields
    0=DISABLE; 1=ENABLE
  [n] CTIMER{n}_CLK_EN (n=0..4) — Enables the CTIMER{n} function clock
0xE44 ECC_ENABLE_CTRL reset 0x3 — RAM ECC Enable Control
  [all] fields
    0=DISABLE (ECC is disabled); 1=ENABLE (ECC is enabled)
  [3] RAMF_RAME_ECC_ENABLE — RAMF and RAME ECC enable
  [2] RAMD_RAMC_ECC_ENABLE — RAMD and RAMC ECC enable
  [1] RAMB_RAMX_ECC_ENABLE — RAMB and RAMX ECC enable
  [0] RAMA_ECC_ENABLE
0xFA0 DEBUG_LOCK_EN reset 0x5 — Control Write Access to Security
  [3:0] LOCK_ALL — Controls write access to the security registers
    0=DISABLE (Any other value than b1010: disables write access to all registers); 10=ENABLE (Enables write access to all registers)
0xFA4 DEBUG_FEATURES reset 0x1555 — Cortex Debug Features Control
  [all] fields
    1=DISABLE (Disables debug); 2=ENABLE (Enables debug)
  [13:12] DSP_DBGDEN — DSP invasive debug control
  [11:10] CPU1_NIDEN — CPU1 non-invasive debug control
  [9:8] CPU1_DBGEN — CPU1 invasive debug control
  [7:6] CPU0_SPNIDEN — CPU0 secure privileged non-invasive debug control
  [5:4] CPU0_SPIDEN — CPU0 secure privileged invasive debug control
  [3:2] CPU0_NIDEN — CPU0 non-invasive debug control
  [1:0] CPU0_DBGEN — CPU0 invasive debug control
0xFA8 DEBUG_FEATURES_DP reset 0x1555 — Cortex Debug Features Control (Duplicate)
  [all] fields
    1=DISABLE (Disables debug); 2=ENABLE (Enables debug)
  [13:12] DSP_DBGEN — DSP invasive debug control
  [11:10] CPU1_NIDEN — CPU1 non-invasive debug control
  [9:8] CPU1_DBGEN — CPU1 invasive debug control
  [7:6] CPU0_SPNIDEN — CPU0 secure privileged non-invasive debug control
  [5:4] CPU0_SPIDEN — CPU0 secure privileged invasive debug control
  [3:2] CPU0_NIDEN — CPU0 non-invasive debug control
  [1:0] CPU0_DBGEN — CPU0 invasive debug control
0xFB4 SWD_ACCESS_CPU0 — CPU0 Software Debug Access
  [31:0] SEC_CODE — CPU0 SWD-AP: 0x12345678
    0=DISABLE (CPU0 DAP is not allowed. Reading back register is read as 0x5.); 0x12345678=ENABLE (Value to write to enable CPU0 SWD access. Reading back register is read as 0xA.)
0xFB8 SWD_ACCESS_CPU1 wo — CPU1 Software Debug Access
  [31:0] SEC_CODE — Security code to allow CPU1 DAP: 0x12345678
    0=DISABLE (CPU1 DAP is not allowed); 0x12345678=ENABLE (Security code to allow CPU1 DAP)
0xFC0 DEBUG_AUTH_BEACON — Debug Authentication BEACON
  [31:0] BEACON — Sets by the debug authentication code in ROM to pass the debug beacons (Credential Beacon and Authentication Beacon) to the application code.
0xFC4 SWD_ACCESS_DSP — DSP Software Debug Access
  [31:0] SEC_CODE — DSP SWD-AP: 0x12345678
    0=DISABLE (DSP DAP is not allowed. Reading back register is read as 0x5.); 0x12345678=ENABLE (Value to write to enable DSP SWD access. Reading back register is read as 0xA.)
0xFF0 JTAG_ID ro reset 0x726402B (reset mask 0xFFFFFFF) — JTAG Chip ID
  [31:0] JTAG_ID — Indicates the device ID
0xFF4 DEVICE_TYPE ro reset not defined
  [31:0] DEVICE_TYPE — Indicates DEVICE TYPE.
0xFF8 DEVICE_ID0 ro (reset mask 0xF00FFF00) — Device ID
  [23:20] ROM_REV_MINOR — ROM revision.
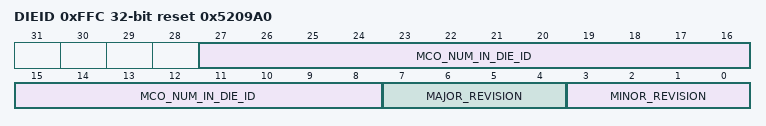
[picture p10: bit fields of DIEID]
0xFFC DIEID ro reset 0x5209A0 (reset mask 0xFFFFF0) — Chip Revision ID and Number
  [27:8] MCO_NUM_IN_DIE_ID — Chip number
  [7:4] MAJOR_REVISION — Chip major revision
  [3:0] MINOR_REVISION — Chip minor revision
